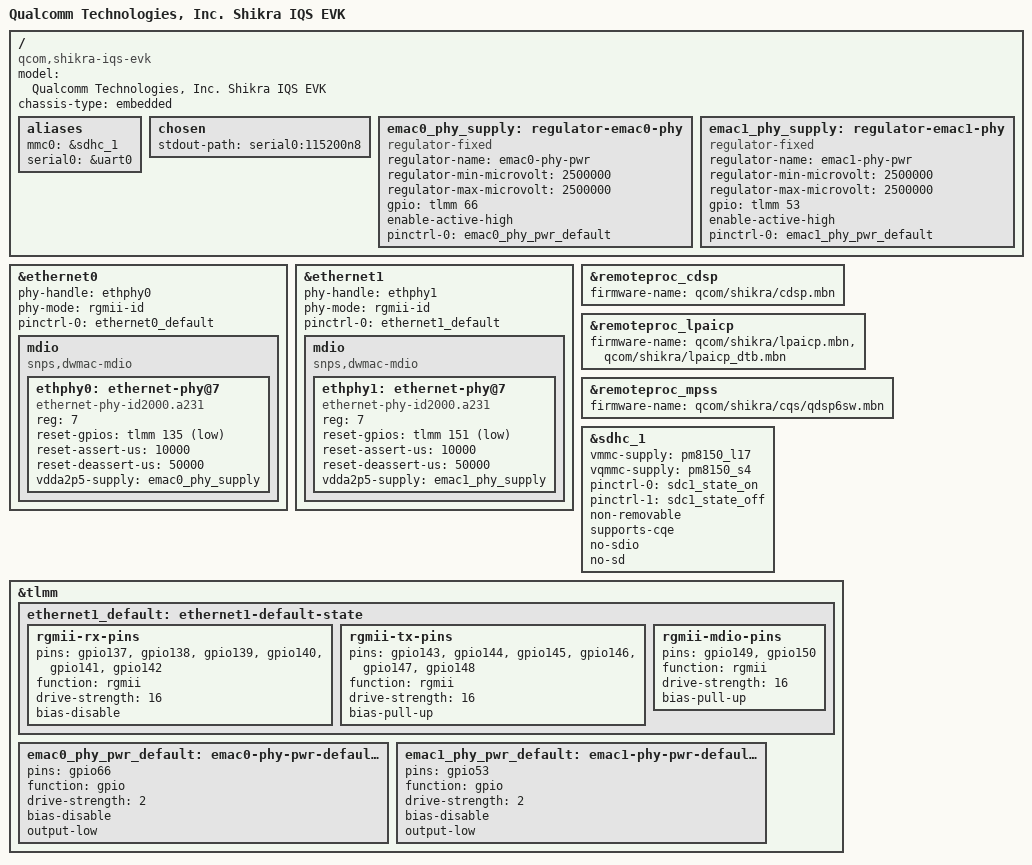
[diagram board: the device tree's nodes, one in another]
// SPDX-License-Identifier: BSD-3-Clause
/*
 * Copyright (c) Qualcomm Technologies, Inc. and/or its subsidiaries.
 */

/dts-v1/;

#include "shikra-iqs-som.dtsi"
#include "shikra-evk.dtsi"

/ {
	model = "Qualcomm Technologies, Inc. Shikra IQS EVK";
	compatible = "qcom,shikra-iqs-evk", "qcom,shikra-iqs-som", "qcom,shikra";
	chassis-type = "embedded";

	aliases {
		mmc0 = &sdhc_1;
		serial0 = &uart0;
	};

	chosen {
		stdout-path = "serial0:115200n8";
	};

	emac0_phy_supply: regulator-emac0-phy {
		compatible = "regulator-fixed";
		regulator-name = "emac0-phy-pwr";
		regulator-min-microvolt = <2500000>;
		regulator-max-microvolt = <2500000>;
		gpio = <&tlmm 66 GPIO_ACTIVE_HIGH>;
		enable-active-high;
		pinctrl-0 = <&emac0_phy_pwr_default>;
		pinctrl-names = "default";
	};

	emac1_phy_supply: regulator-emac1-phy {
		compatible = "regulator-fixed";
		regulator-name = "emac1-phy-pwr";
		regulator-min-microvolt = <2500000>;
		regulator-max-microvolt = <2500000>;
		gpio = <&tlmm 53 GPIO_ACTIVE_HIGH>;
		enable-active-high;
		pinctrl-0 = <&emac1_phy_pwr_default>;
		pinctrl-names = "default";
	};
};

&ethernet0 {
	phy-handle = <&ethphy0>;
	phy-mode = "rgmii-id";

	pinctrl-0 = <&ethernet0_default>;
	pinctrl-names = "default";

	mdio {
		compatible = "snps,dwmac-mdio";
		#address-cells = <1>;
		#size-cells = <0>;

		ethphy0: ethernet-phy@7 {
			compatible = "ethernet-phy-id2000.a231";
			reg = <7>;
			reset-gpios = <&tlmm 135 GPIO_ACTIVE_LOW>;
			reset-assert-us = <10000>;
			reset-deassert-us = <50000>;
			vdda2p5-supply = <&emac0_phy_supply>;
		};
	};

	status = "okay";
};

&ethernet1 {
	phy-handle = <&ethphy1>;
	phy-mode = "rgmii-id";

	pinctrl-0 = <&ethernet1_default>;
	pinctrl-names = "default";

	mdio {
		compatible = "snps,dwmac-mdio";
		#address-cells = <1>;
		#size-cells = <0>;

		ethphy1: ethernet-phy@7 {
			compatible = "ethernet-phy-id2000.a231";
			reg = <7>;
			reset-gpios = <&tlmm 151 GPIO_ACTIVE_LOW>;
			reset-assert-us = <10000>;
			reset-deassert-us = <50000>;
			vdda2p5-supply = <&emac1_phy_supply>;
		};
	};

	status = "okay";
};

&remoteproc_cdsp {
	firmware-name = "qcom/shikra/cdsp.mbn";

	status = "okay";
};

&remoteproc_lpaicp {
	firmware-name = "qcom/shikra/lpaicp.mbn",
			"qcom/shikra/lpaicp_dtb.mbn";

	status = "okay";
};

&remoteproc_mpss {
	firmware-name = "qcom/shikra/cqs/qdsp6sw.mbn";

	status = "okay";
};

&sdhc_1 {
	vmmc-supply = <&pm8150_l17>;
	vqmmc-supply = <&pm8150_s4>;

	pinctrl-0 = <&sdc1_state_on>;
	pinctrl-1 = <&sdc1_state_off>;
	pinctrl-names = "default", "sleep";

	non-removable;
	supports-cqe;
	no-sdio;
	no-sd;

	status = "okay";
};

&tlmm {
	/* EMAC1 RGMII pins are IQS-specific (gpio137-150). */
	ethernet1_default: ethernet1-default-state {
		rgmii-rx-pins {
			pins = "gpio137", "gpio138", "gpio139",
			       "gpio140", "gpio141", "gpio142";
			function = "rgmii";
			drive-strength = <16>;
			bias-disable;
		};

		rgmii-tx-pins {
			pins = "gpio143", "gpio144", "gpio145",
			       "gpio146", "gpio147", "gpio148";
			function = "rgmii";
			drive-strength = <16>;
			bias-pull-up;
		};

		rgmii-mdio-pins {
			pins = "gpio149", "gpio150";
			function = "rgmii";
			drive-strength = <16>;
			bias-pull-up;
		};
	};

	emac0_phy_pwr_default: emac0-phy-pwr-default-state {
		pins = "gpio66";
		function = "gpio";
		drive-strength = <2>;
		bias-disable;
		output-low;
	};

	emac1_phy_pwr_default: emac1-phy-pwr-default-state {
		pins = "gpio53";
		function = "gpio";
		drive-strength = <2>;
		bias-disable;
		output-low;
	};
};
